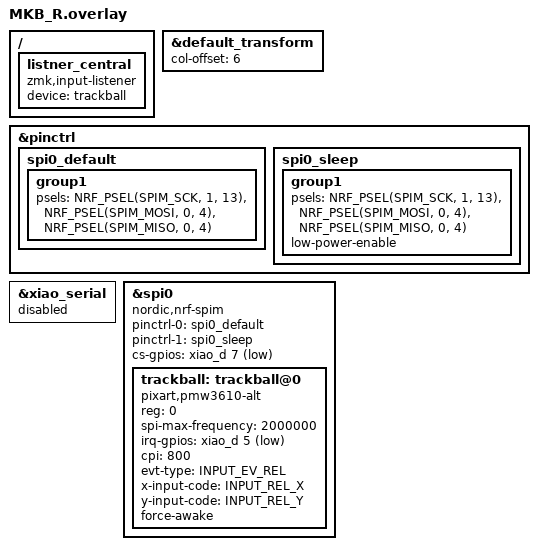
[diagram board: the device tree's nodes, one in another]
#include <zephyr/dt-bindings/input/input-event-codes.h>
#include "KB_Base.dtsi"

&default_transform {
    col-offset = <6>;
};

/{
  listner_central: listner_central {
    compatible = "zmk,input-listener";
    status = "okay";
    device = <&trackball>;
  };    
};

&pinctrl {
    spi0_default: spi0_default {
        group1 {
            psels = <NRF_PSEL(SPIM_SCK,  1, 13)>,
                    <NRF_PSEL(SPIM_MOSI, 0, 4)>,
                    <NRF_PSEL(SPIM_MISO, 0, 4)>;
        };
    };

    spi0_sleep: spi0_sleep {
        group1 {
            psels = <NRF_PSEL(SPIM_SCK,  1, 13)>,
                    <NRF_PSEL(SPIM_MOSI, 0, 4)>,
                    <NRF_PSEL(SPIM_MISO, 0, 4)>;
            low-power-enable;
        };
    };
};

&xiao_serial { status = "disabled"; };

&spi0 {
    status = "okay";
    compatible = "nordic,nrf-spim";
    pinctrl-0 = <&spi0_default>;
    pinctrl-1 = <&spi0_sleep>;
    pinctrl-names = "default", "sleep";
    cs-gpios =  <&xiao_d 7 GPIO_ACTIVE_LOW>;

    trackball: trackball@0 {
        status = "okay";
        compatible = "pixart,pmw3610-alt";
        reg = <0>;
        spi-max-frequency = <2000000>;
        irq-gpios = <&xiao_d 5 (GPIO_ACTIVE_LOW | GPIO_PULL_UP)>;
        cpi = <800>;
        evt-type = <INPUT_EV_REL>;
        x-input-code = <INPUT_REL_X>;
        y-input-code = <INPUT_REL_Y>;
        force-awake;
    };
};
